AUTOSAR XML (schema 4-2-1)
package /RootP_ASWC_M6
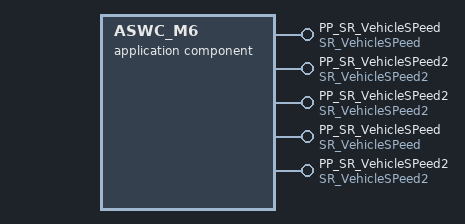
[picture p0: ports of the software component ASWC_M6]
  application sw component type ASWC_M6
    5 x provide port:
      PP_SR_VehicleSPeed: provided-interface=SR_VehicleSPeed
      PP_SR_VehicleSPeed2: provided-interface=SR_VehicleSPeed2
      PP_SR_VehicleSPeed2: provided-interface=SR_VehicleSPeed2
      PP_SR_VehicleSPeed: provided-interface=SR_VehicleSPeed
      PP_SR_VehicleSPeed2: provided-interface=SR_VehicleSPeed2
package /RootP_Composition
  composition sw component type Compo_VSM
    component Instance_ASWC_M6: type=ASWC_M6
